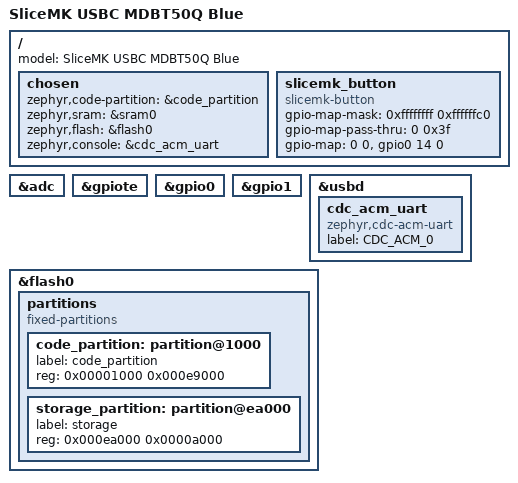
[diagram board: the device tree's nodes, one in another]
/dts-v1/;
#include <nordic/nrf52840_qiaa.dtsi>

/ {
    model = "SliceMK USBC MDBT50Q Blue";

    chosen {
        zephyr,code-partition = &code_partition;
        zephyr,sram = &sram0;
        zephyr,flash = &flash0;
        zephyr,console = &cdc_acm_uart;
    };

    // The USB C dongle doesn't have anything beside the reset button but ZMK
    // needs something to be defined for kscan so define an arbitrary GPIO pin.
    slicemk_button: slicemk_button {
        compatible = "slicemk-button";
        #gpio-cells = <2>;
        gpio-map-mask = <0xffffffff 0xffffffc0>;
        gpio-map-pass-thru = <0 0x3f>;
        gpio-map = <0 0 &gpio0 14 0>;
    };
};

&adc {
    status = "okay";
};

&gpiote {
    status = "okay";
};

&gpio0 {
    status = "okay";
};

&gpio1 {
    status = "okay";
};

&usbd {
    status = "okay";
    cdc_acm_uart: cdc_acm_uart {
        compatible = "zephyr,cdc-acm-uart";
        label = "CDC_ACM_0";
    };
};

&flash0 {
    partitions {
        compatible = "fixed-partitions";
        #address-cells = <1>;
        #size-cells = <1>;

        // Application starts at 0x1000 after the MBR.
        code_partition: partition@1000 {
            label = "code_partition";
            reg = <0x00001000 0x000e9000>;
        };

        // Define storage partition before the bootloader, which starts at
        // 0xf4000. The storage partition has been 10 pages since Adafruit
        // bootloader version 0.6.0.
        storage_partition: partition@ea000 {
            label = "storage";
            reg = <0x000ea000 0x0000a000>;
        };
    };
};
